# TMS320F28M35x_C28x register map
Vendor: Texas Instruments; Series: C2000 Concerto F28M35x; File version: 0.2.0-generated
Registers are 32-bit, read-write, reset 0x0 unless marked. A register's access mark holds for its fields unless they carry their own. Offsets are from the block's base; [hi:lo] are bit positions; {n}, {i} and the like mark numbered series.

## DEVEMU — DEV EMU REGS Registers
Base 0x00001100
0x00 DEVICECNF — Device Configuration Register
0x04 PARTID 16-bit — Device ID Register
0x06 REVID 16-bit — Revision Register
{0xC+4i} CCNF{i} (i=0..4) — C28 Peripheral Configuration {i}
0x8C MEMCNF — M3 Memory Configuartion Register

## CSM — DCSM REGS Registers
Base 0x000015C0
{0x0+4i} Z1_CSMKEY{i} (i=0..3) — CSMKEY{i} Register for C28X-Zone-1 security Zone
0x1E Z1_CR 16-bit — Status and Control Register for C28X-Zone-1 security Zone
0x20 Z1_ECSLKEY0 — ECSLKEY0 Register for C28X-Zone-1 security Zone
0x24 Z1_ECSLKEY1 — ECSLKEY1 Register for C28X-Zone-1 security Zone
0x2A Z1_EXEONLYR 16-bit — Execute-Only Select Register for flash sectors

## ADC1RESULT — ADC Mirror Registers
Base 0x00001600
Same registers: ADC2RESULT 0x00001680
{0x0+2i} ADCRESULT{i} 16-bit (i=0..15) — Conversion Result Buffer {i}

## CPUTIMER — CPU Timer Registers
Base 0x00001800
{0x0+0x10*i} TIMER{i}TIM 16-bit (i=0..2) — CPU-Timer {i}, Counter Register
{0x2+0x10*i} TIMER{i}TIMH 16-bit (i=0..2) — CPU-Timer {i}, Counter Register High
{0x4+0x10*i} TIMER{i}PRD 16-bit (i=0..2) — CPU-Timer {i}, Period Register
{0x6+0x10*i} TIMER{i}PRDH 16-bit (i=0..2) — CPU-Timer {i}, Period Register High
{0x8+0x10*i} TIMER{i}TCR 16-bit (i=0..2) — CPU-Timer {i}, Control Register
{0xC+0x10*i} TIMER{i}TPR 16-bit (i=0..2) — CPU-Timer {i}, Prescale Register
{0xE+0x10*i} TIMER{i}TPRH 16-bit (i=0..2) — CPU-Timer {i}, Prescale Register High

## PIECTRL — Peripheral Interrupt Expansion Registers
Base 0x000019C0
0x00 PIECTRL 16-bit — PIE, Control Register
0x02 PIEACK 16-bit — PIE, Acknowledge Register
{0x0+4i} PIEIER{i} 16-bit (i=1..12) — PIE, INT{i} Group Enable Register
{0x2+4i} PIEIFR{i} 16-bit (i=1..12) — PIE, INT{i} Group Flag Register

## FPU — Floating-Point Unit Single Precision Registers
Base 0x00001E00
0x00 RB — Repeat Block Register
  [31] RAS — Repeat block shadow active
  [30] RA — Repeat block active
  [31:29] RSIZE — Repeat block size
  [28:22] RE — Repeat block end
  [30:15] RC — Repeat count
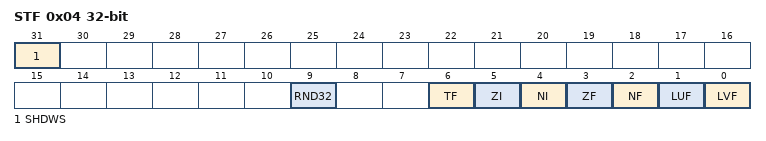
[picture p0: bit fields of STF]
0x04 STF — Floating-Point Status Register
  [31] SHDWS — Shadow mode status
  [9] RND32 — Rounding mode
  [6] TF — Test flag
  [5] ZI — Zero integer flag
  [4] NI — Negative integer flag
  [3] ZF — Zero float flag
  [2] NF — Negative flaot flag
  [1] LUF — Latched underflow
  [0] LVF — Latched overflow
{0x24+8i} R{i}H (i=0..7)

## DMA — DMA Registers
Base 0x00002000
0x00 DMACTRL 16-bit — DMA Control Register
0x02 DEBUGCTRL 16-bit — Debug Control Register
0x04 REVISION 16-bit — Peripheral Revision Register
0x08 PRIORITYCTRL1 16-bit — Priority Control Register 1
0x0C PRIORITYSTAT 16-bit — Priority Status Register
{0x0+0x40*i} DMACH{i}_MODE 16-bit (i=1..6) — DMA Channel {i} Mode Register
{0x2+0x40*i} DMACH{i}_CONTROL 16-bit (i=1..6) — DMA Channel {i} Control Register
{0x4+0x40*i} DMACH{i}_BURST_SIZE 16-bit (i=1..6) — DMA Channel {i} Burst Size Register
{0x6+0x40*i} DMACH{i}_BURST_COUNT 16-bit (i=1..6) — DMA Channel {i} Burst Count Register
{0x8+0x40*i} DMACH{i}_SRC_BURST_STEP 16-bit (i=1..6) — DMA Channel {i} Source Burst Step Size Register
{0xA+0x40*i} DMACH{i}_DST_BURST_STEP 16-bit (i=1..6) — DMA Channel {i} Destination Burst Step Size Register
{0xC+0x40*i} DMACH{i}_TRANSFER_SIZE 16-bit (i=1..6) — DMA Channel {i} Transfer Size Register
{0xE+0x40*i} DMACH{i}_TRANSFER_COUNT 16-bit (i=1..6) — DMA Channel {i} Transfer Count Register
{0x10+0x40*i} DMACH{i}_SRC_TRANSFER_STEP 16-bit (i=1..6) — DMA Channel {i} Source Transfer Step Size Register
{0x12+0x40*i} DMACH{i}_DST_TRANSFER_STEP 16-bit (i=1..6) — DMA Channel {i} Destination Transfer Step Size Register
{0x14+0x40*i} DMACH{i}_SRC_WRAP_SIZE 16-bit (i=1..6) — DMA Channel {i} Source Wrap Size Register
{0x16+0x40*i} DMACH{i}_SRC_WRAP_COUNT 16-bit (i=1..6) — DMA Channel {i} Source Wrap Count Register
{0x18+0x40*i} DMACH{i}_SRC_WRAP_STEP 16-bit (i=1..6) — DMA Channel {i} Source Wrap Step Size Register
{0x1A+0x40*i} DMACH{i}_DST_WRAP_SIZE 16-bit (i=1..6) — DMA Channel {i} Destination Wrap Size Register
{0x1C+0x40*i} DMACH{i}_DST_WRAP_COUNT 16-bit (i=1..6) — DMA Channel {i} Destination Wrap Count Register
{0x1E+0x40*i} DMACH{i}_DST_WRAP_STEP 16-bit (i=1..6) — DMA Channel {i} Destination Wrap Step Size Register
{0x20+0x40*i} DMACH{i}_SRC_BEG_ADDR_SHADOW (i=1..6) — DMA Channel {i} Shadow Source Begin Register
{0x24+0x40*i} DMACH{i}_SRC_ADDR_SHADOW (i=1..6) — DMA Channel {i} Shadow Source Current Address Register
{0x28+0x40*i} DMACH{i}_SRC_BEG_ADDR_ACTIVE (i=1..6) — DMA Channel {i} Active Source Begin Register
{0x2C+0x40*i} DMACH{i}_SRC_ADDR_ACTIVE (i=1..6) — DMA Channel {i} Active Source Current Address Register
{0x30+0x40*i} DMACH{i}_DST_BEG_ADDR_SHADOW (i=1..6) — DMA Channel {i} Shadow Destination Begin Register
{0x34+0x40*i} DMACH{i}_DST_ADDR_SHADOW (i=1..6) — DMA Channel {i} Shadow Destination Current Address Register
{0x38+0x40*i} DMACH{i}_DST_BEG_ADDR_ACTIVE (i=1..6) — DMA Channel {i} Active Destination Begin Register
{0x3C+0x40*i} DMACH{i}_DST_ADDR_ACTIVE (i=1..6) — DMA Channel {i} Active Destination Current Address Register
